# TM4C129ENCPDT register map
File version: 1.0
CPU: CORTEX_M4 1.0, other endian, MPU, FPU, 3 interrupt priority bits
Registers are 32-bit, read-write, reset 0x0 unless marked. A register's access mark holds for its fields unless they carry their own. Offsets are from the block's base; [hi:lo] are bit positions; {n}, {i} and the like mark numbered series.

## SSI0 — SSI register offsets
Base 0x40008000
Same registers: SSI1 0x40009000, SSI2 0x4000A000, SSI3 0x4000B000
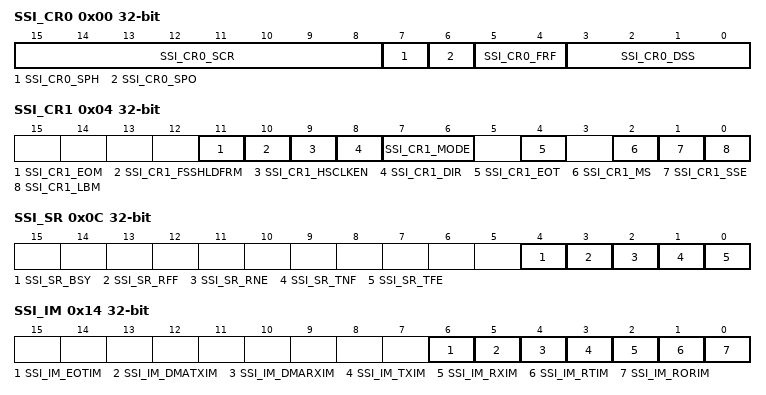
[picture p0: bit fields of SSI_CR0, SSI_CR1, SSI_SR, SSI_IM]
0x00 SSI_CR0 — SSI Control 0
  [15:8] SSI_CR0_SCR — [15:8] SSI Serial Clock Rate
  [7] SSI_CR0_SPH — [7:7] SSI Serial Clock Phase
  [6] SSI_CR0_SPO — [6:6] SSI Serial Clock Polarity
  [5:4] SSI_CR0_FRF — [5:4] SSI Frame Format Select
    0=SSI_CR0_FRF_MOTO (Freescale SPI Frame Format); 16=SSI_CR0_FRF_TI (Synchronous Serial Frame Format)
  [3:0] SSI_CR0_DSS — [3:0] SSI Data Size Select
    {v}={v+1}-bit data (v=3..15)
0x04 SSI_CR1 — SSI Control 1
  [11] SSI_CR1_EOM — [11:11] Stop Frame (End of Message)
  [10] SSI_CR1_FSSHLDFRM — [10:10] FSS Hold Frame
  [9] SSI_CR1_HSCLKEN — [9:9] High Speed Clock Enable
  [8] SSI_CR1_DIR — [8:8] SSI Direction of Operation
  [7:6] SSI_CR1_MODE — [7:6] SSI Mode
    0=SSI_CR1_MODE_LEGACY (Legacy SSI mode); 64=SSI_CR1_MODE_BI (Bi-SSI mode); 128=SSI_CR1_MODE_QUAD (Quad-SSI Mode); 192=SSI_CR1_MODE_ADVANCED (Advanced SSI Mode with 8-bit packet size)
  [4] SSI_CR1_EOT — [4:4] End of Transmission
  [2] SSI_CR1_MS — [2:2] SSI Master/Slave Select
  [1] SSI_CR1_SSE — [1:1] SSI Synchronous Serial Port Enable
  [0] SSI_CR1_LBM — [0:0] SSI Loopback Mode
0x08 SSI_DR — SSI Data
  [15:0] SSI_DR_DATA — [15:0] SSI Receive/Transmit Data
0x0C SSI_SR — SSI Status
  [4] SSI_SR_BSY — [4:4] SSI Busy Bit
  [3] SSI_SR_RFF — [3:3] SSI Receive FIFO Full
  [2] SSI_SR_RNE — [2:2] SSI Receive FIFO Not Empty
  [1] SSI_SR_TNF — [1:1] SSI Transmit FIFO Not Full
  [0] SSI_SR_TFE — [0:0] SSI Transmit FIFO Empty
0x10 SSI_CPSR — SSI Clock Prescale
  [7:0] SSI_CPSR_CPSDVSR — [7:0] SSI Clock Prescale Divisor
0x14 SSI_IM — SSI Interrupt Mask
  [6] SSI_IM_EOTIM — [6:6] End of Transmit Interrupt Mask
  [5] SSI_IM_DMATXIM — [5:5] SSI Transmit DMA Interrupt Mask
  [4] SSI_IM_DMARXIM — [4:4] SSI Receive DMA Interrupt Mask
  [3] SSI_IM_TXIM — [3:3] SSI Transmit FIFO Interrupt Mask
  [2] SSI_IM_RXIM — [2:2] SSI Receive FIFO Interrupt Mask
  [1] SSI_IM_RTIM — [1:1] SSI Receive Time-Out Interrupt Mask
  [0] SSI_IM_RORIM — [0:0] SSI Receive Overrun Interrupt Mask
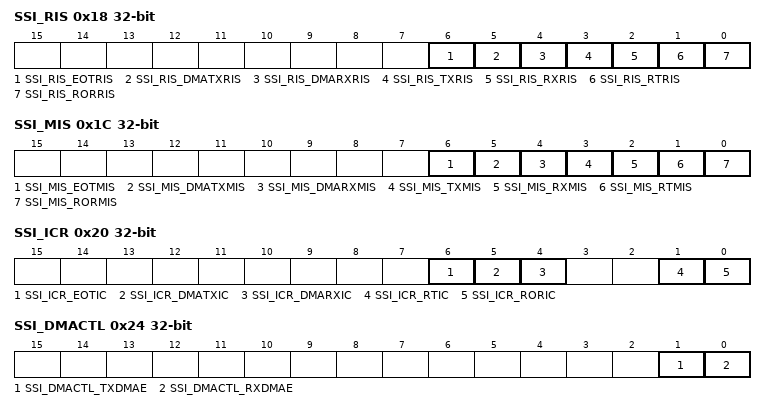
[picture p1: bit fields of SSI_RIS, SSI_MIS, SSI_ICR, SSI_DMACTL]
0x18 SSI_RIS — SSI Raw Interrupt Status
  [6] SSI_RIS_EOTRIS — [6:6] End of Transmit Raw Interrupt Status
  [5] SSI_RIS_DMATXRIS — [5:5] SSI Transmit DMA Raw Interrupt Status
  [4] SSI_RIS_DMARXRIS — [4:4] SSI Receive DMA Raw Interrupt Status
  [3] SSI_RIS_TXRIS — [3:3] SSI Transmit FIFO Raw Interrupt Status
  [2] SSI_RIS_RXRIS — [2:2] SSI Receive FIFO Raw Interrupt Status
  [1] SSI_RIS_RTRIS — [1:1] SSI Receive Time-Out Raw Interrupt Status
  [0] SSI_RIS_RORRIS — [0:0] SSI Receive Overrun Raw Interrupt Status
0x1C SSI_MIS — SSI Masked Interrupt Status
  [6] SSI_MIS_EOTMIS — [6:6] End of Transmit Masked Interrupt Status
  [5] SSI_MIS_DMATXMIS — [5:5] SSI Transmit DMA Masked Interrupt Status
  [4] SSI_MIS_DMARXMIS — [4:4] SSI Receive DMA Masked Interrupt Status
  [3] SSI_MIS_TXMIS — [3:3] SSI Transmit FIFO Masked Interrupt Status
  [2] SSI_MIS_RXMIS — [2:2] SSI Receive FIFO Masked Interrupt Status
  [1] SSI_MIS_RTMIS — [1:1] SSI Receive Time-Out Masked Interrupt Status
  [0] SSI_MIS_RORMIS — [0:0] SSI Receive Overrun Masked Interrupt Status
0x20 SSI_ICR — SSI Interrupt Clear
  [6] SSI_ICR_EOTIC — [6:6] End of Transmit Interrupt Clear
  [5] SSI_ICR_DMATXIC — [5:5] SSI Transmit DMA Interrupt Clear
  [4] SSI_ICR_DMARXIC — [4:4] SSI Receive DMA Interrupt Clear
  [1] SSI_ICR_RTIC — [1:1] SSI Receive Time-Out Interrupt Clear
  [0] SSI_ICR_RORIC — [0:0] SSI Receive Overrun Interrupt Clear
0x24 SSI_DMACTL — SSI DMA Control
  [1] SSI_DMACTL_TXDMAE — [1:1] Transmit DMA Enable
  [0] SSI_DMACTL_RXDMAE — [0:0] Receive DMA Enable
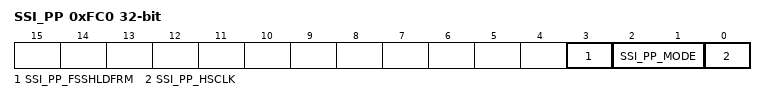
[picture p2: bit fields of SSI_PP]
0xFC0 SSI_PP — SSI Peripheral Properties
  [3] SSI_PP_FSSHLDFRM — [3:3] FSS Hold Frame Capability
  [2:1] SSI_PP_MODE — [2:1] Mode of Operation
    0=SSI_PP_MODE_LEGACY (Legacy SSI mode); 2=SSI_PP_MODE_ADVBI (Legacy mode, Advanced SSI mode and Bi-SSI mode enabled); 4=SSI_PP_MODE_ADVBIQUAD (Legacy mode, Advanced mode, Bi-SSI and Quad-SSI mode enabled)
  [0] SSI_PP_HSCLK — [0:0] High Speed Capability
0xFC8 SSI_CC — SSI Clock Configuration
  [3:0] SSI_CC_CS — [3:0] SSI Baud Clock Source
    0=SSI_CC_CS_SYSPLL (System clock (based on clock source and divisor factor)); 5=SSI_CC_CS_PIOSC (PIOSC)
